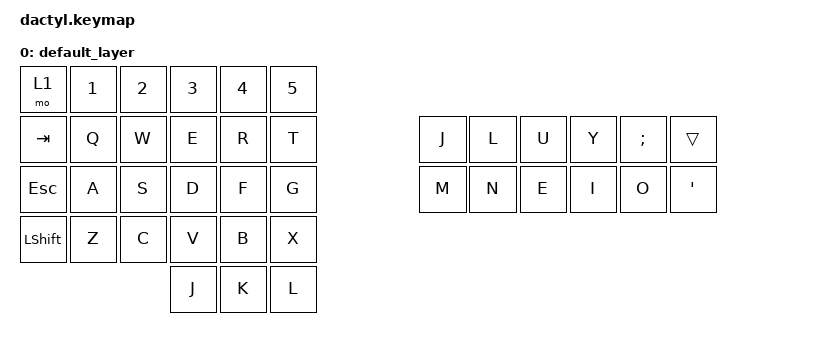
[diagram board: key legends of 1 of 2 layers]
#include <behaviors.dtsi>
#include <dt-bindings/zmk/keys.h>
#include <dt-bindings/zmk/bt.h>

/ {  
    keymap {
        compatible = "zmk,keymap";

        default_layer {
            bindings = <
                &mo 1     &kp N1    &kp N2   &kp N3    &kp N4    &kp N5           
                &kp TAB   &kp Q     &kp W    &kp E     &kp R     &kp T                                                 &kp J     &kp L     &kp U     &kp Y     &kp SEMI    &trans
                &kp ESC   &kp A     &kp S    &kp D     &kp F     &kp G                                                 &kp M     &kp N     &kp E     &kp I     &kp O      &kp SQT
                &kp LSHFT &kp Z  	&kp C    &kp V     &kp B     &kp X 
                                             &kp J     &kp K     &kp L   
            >;
        }; 
        
        bt_layer {
            bindings = <
                &mo 0            &none            &bootloader    &none  &none &none
                &none            &none            &bt BT_CLR     &none  &none &none
                &bt BT_SEL 0     &bt BT_SEL 1     &bt BT_SEL 2   &none  &none &none
                &none            &none            &none          &none  &none &none
                                                                 &none  &none &none
            >;
        };
    };
};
